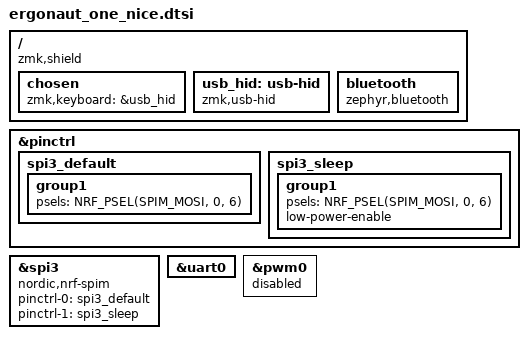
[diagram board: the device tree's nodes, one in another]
#include <dt-bindings/zmk/matrix_transform.h>

/ {
    compatible = "zmk,shield";

    chosen {
        zmk,keyboard = &usb_hid; // Указывает, что это HID устройство
    };

    usb_hid: usb-hid {
        compatible = "zmk,usb-hid";
    };

    bluetooth: bluetooth {
        status = "okay";
        compatible = "zephyr,bluetooth";
    };
};
&pinctrl {
    spi3_default: spi3_default {
        group1 {
            psels = <NRF_PSEL(SPIM_MOSI, 0, 6)>;
        };
    };

    spi3_sleep: spi3_sleep {
        group1 {
            psels = <NRF_PSEL(SPIM_MOSI, 0, 6)>;
            low-power-enable;
        };
    };
};

&spi3 {
    compatible = "nordic,nrf-spim";
    status = "okay";

    pinctrl-0 = <&spi3_default>;
    pinctrl-1 = <&spi3_sleep>;
    pinctrl-names = "default", "sleep";

};

&spi3 { status = "ok"; };
&uart0 { status = "ok"; };
&pwm0 { status = "disabled"; };
